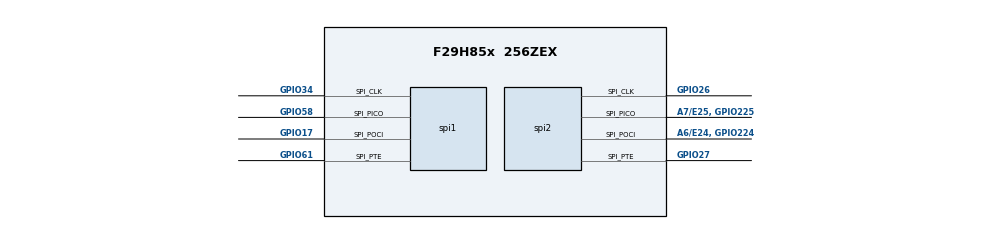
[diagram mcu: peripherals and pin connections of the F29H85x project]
/**
 * @cliArgs --device "F29H85x" --package "256ZEX" --part "F29H85x_256ZEX" --context "CPU1" --product "MCU_SDK_F29H85x@1.02.02.00"
 * @versions {"tool":"1.25.0+4237"}
 */

    
const divider15       = system.clockTree["PLL_REFDIV"];
divider15.divideValue = 1;

const multiplier1         = system.clockTree["PLL_IMULT"];
multiplier1.multiplyValue = 40;

const mux7       = system.clockTree["OSCCLKSRCSEL"];
mux7.inputSelect = "INTOSC2";

/**
 * Import the modules used in this configuration.
 */
const jtag  = scripting.addModule("/driverlib/jtag.js");
const spi   = scripting.addModule("/driverlib/spi.js", {}, false);
const spi1  = spi.addInstance();
const spi2  = spi.addInstance();

/**
 * Write custom configuration values to the imported modules.
 */
spi1.bitRate                 = 2000000;
spi1.emulationMode           = "SPI_EMULATION_FREE_RUN";
spi1.$name                   = "SPIA_peripheral";
spi1.useInterrupts           = false;
spi1.useFifo                 = false;
spi1.spi.$assign             = "SPIA";
spi1.spi.spi_picoPin.$assign = "GPIO58";
spi1.spi.spi_pociPin.$assign = "GPIO17";
spi1.spi.spi_clkPin.$assign  = "GPIO34";
spi1.spi.spi_ptePin.$assign  = "GPIO61";
spi1.periphClock.$name       = "driverlib_perClock0";
spi1.periphConfig.$name      = "driverlib_perConfig0";

spi2.bitRate                 = 2000000;
spi2.emulationMode           = "SPI_EMULATION_FREE_RUN";
spi2.$name                   = "SPIB_controller";
spi2.useFifo                 = false;
spi2.useInterrupts           = false;
spi2.mode                    = "SPI_MODE_CONTROLLER";
spi2.spi.$assign             = "SPIB";
spi2.spi.spi_picoPin.$assign = "A7/E25, GPIO225";
spi2.spi.spi_pociPin.$assign = "A6/E24, GPIO224";
spi2.spi.spi_clkPin.$assign  = "GPIO26";
spi2.spi.spi_ptePin.$assign  = "GPIO27";
spi2.periphClock.$name       = "driverlib_perClock1";
spi2.periphConfig.$name      = "driverlib_perConfig1";
